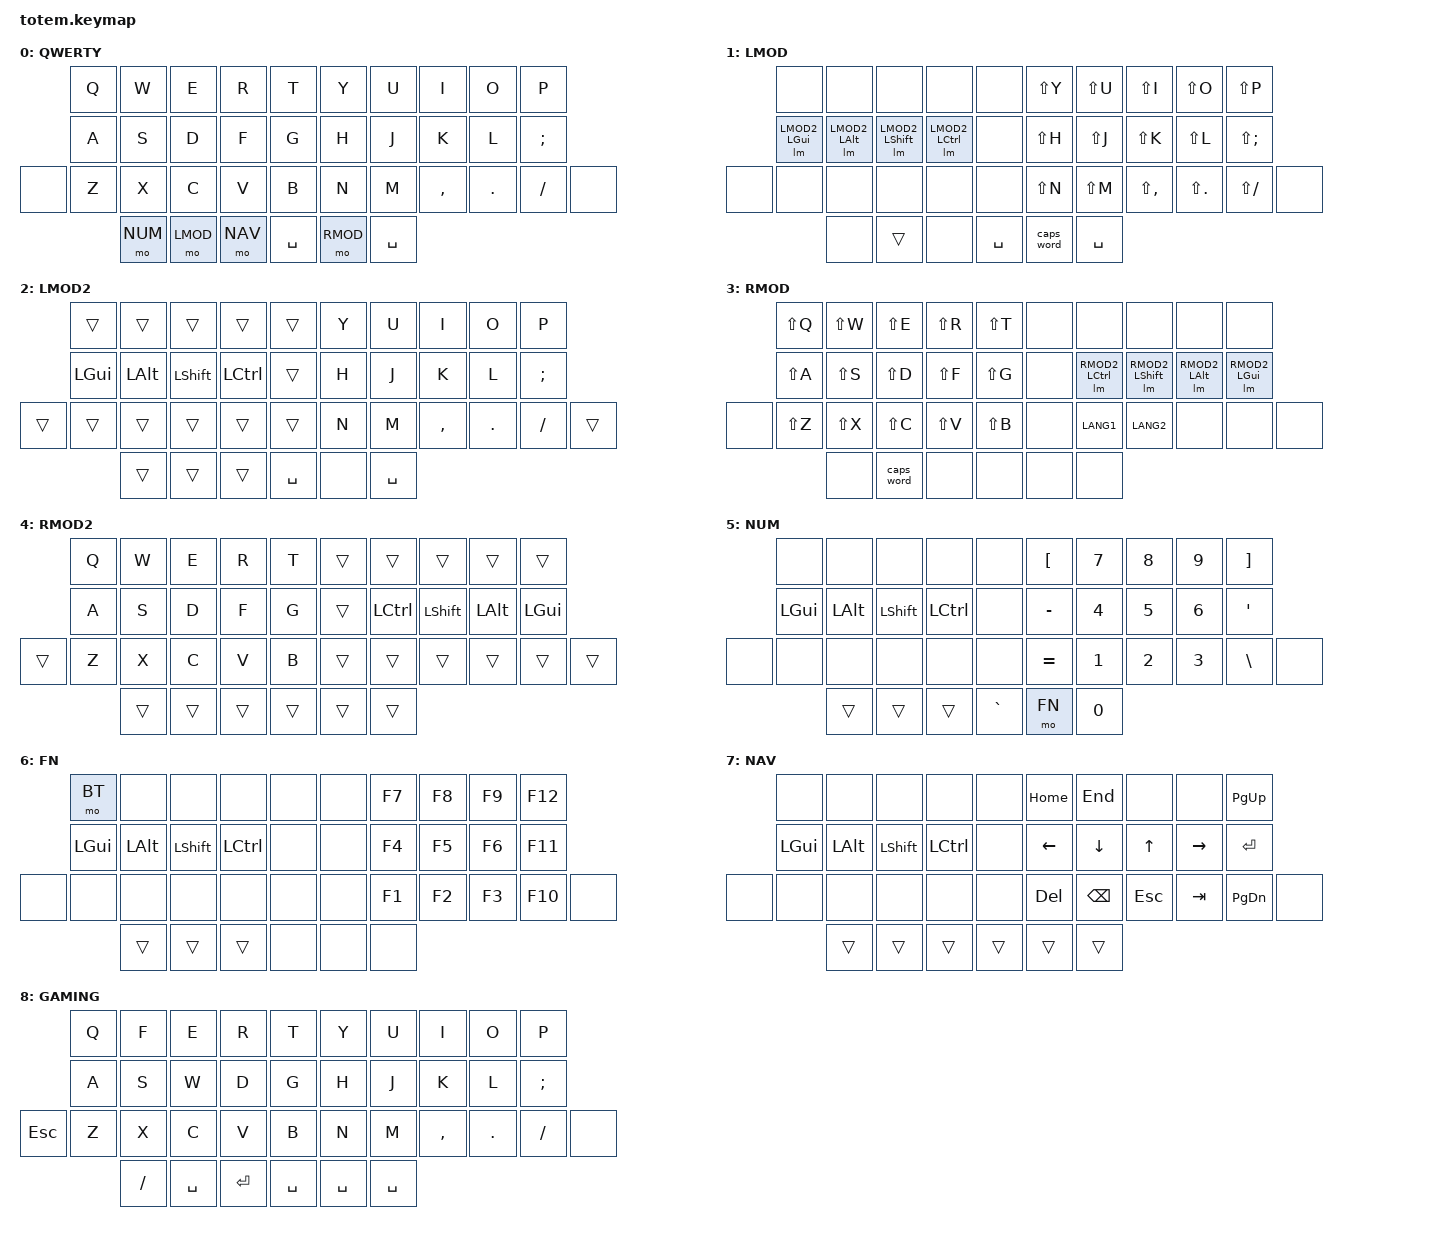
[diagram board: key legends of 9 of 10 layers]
// QMK default keymap port for Totem
// Mirrors qmk_firmware/keyboards/totem/keymaps/default

#include <behaviors.dtsi>
#include <dt-bindings/zmk/bt.h>
#include <dt-bindings/zmk/keys.h>

#define QWERTY 0
#define LMOD   1
#define LMOD2  2
#define RMOD   3
#define RMOD2  4
#define NUM    5
#define FN     6
#define NAV    7
#define GAMING 8
#define BT    9


/ {
    behaviors {
        lm: lm {
            compatible = "zmk,behavior-macro-two-param";
            wait-ms = <0>;
            tap-ms = <0>;
            #binding-cells = <2>;
            bindings
                = <&macro_param_1to1>
                , <&macro_press &mo MACRO_PLACEHOLDER>
                , <&macro_param_2to1>
                , <&macro_press &kp MACRO_PLACEHOLDER>
                , <&macro_pause_for_release>
                , <&macro_param_2to1>
                , <&macro_release &kp MACRO_PLACEHOLDER>
                , <&macro_param_1to1>
                , <&macro_release &mo MACRO_PLACEHOLDER>
                ;
        };
    };

    keymap {
        compatible = "zmk,keymap";

        qwerty_layer {
            label = "QWERTY";
            bindings = <
             &kp Q       &kp W       &kp E        &kp R        &kp T        &kp Y     &kp U            &kp I        &kp O       &kp P
             &kp A       &kp S       &kp D        &kp F        &kp G        &kp H     &kp J            &kp K        &kp L       &kp SEMICOLON
    &none      &kp Z       &kp X        &kp C        &kp V        &kp B        &kp N     &kp M            &kp COMMA    &kp DOT     &kp FSLH     &none
                             &mo NUM    &mo LMOD     &mo NAV      &kp SPACE    &mo RMOD  &kp SPACE
            >;
        };

        lmod_layer {
            label = "LMOD";
            bindings = <
             &none        &none        &none         &none         &none        &kp LS(Y)   &kp LS(U)        &kp LS(I)        &kp LS(O)         &kp LS(P)
             &lm LMOD2 LGUI &lm LMOD2 LALT &lm LMOD2 LSHFT &lm LMOD2 LCTRL &none        &kp LS(H)   &kp LS(J)        &kp LS(K)        &kp LS(L)         &kp LS(SEMICOLON)
    &none       &none        &none         &none         &none        &none        &kp LS(N)   &kp LS(M)        &kp LS(COMMA)    &kp LS(DOT)       &kp LS(FSLH)    &none
                              &none        &trans        &none        &kp SPACE    &caps_word  &kp SPACE
            >;
        };

        lmod2_layer {
            label = "LMOD2";
            bindings = <
             &trans   &trans   &trans   &trans   &trans   &kp Y     &kp U    &kp I    &kp O   &kp P
             &kp LGUI &kp LALT &kp LSHFT &kp LCTRL &trans   &kp H     &kp J    &kp K    &kp L   &kp SEMICOLON
    &trans  &trans   &trans   &trans   &trans   &trans   &kp N     &kp M    &kp COMMA &kp DOT &kp FSLH &trans
                         &trans  &trans  &trans  &kp SPACE  &none     &kp SPACE
            >;
        };

        rmod_layer {
            label = "RMOD";
            bindings = <
             &kp LS(Q)   &kp LS(W)   &kp LS(E)   &kp LS(R)   &kp LS(T)   &none        &none         &none          &none          &none
             &kp LS(A)   &kp LS(S)   &kp LS(D)   &kp LS(F)   &kp LS(G)   &none        &lm RMOD2 LCTRL &lm RMOD2 LSHFT &lm RMOD2 LALT &lm RMOD2 LGUI
    &none    &kp LS(Z)   &kp LS(X)   &kp LS(C)   &kp LS(V)   &kp LS(B)   &none        &kp LANG1     &kp LANG2      &none          &none        &none
                          &none       &caps_word  &none       &none        &none         &none
            >;
        };

        rmod2_layer {
            label = "RMOD2";
            bindings = <
             &kp Q   &kp W   &kp E   &kp R   &kp T   &trans &trans &trans &trans &trans
             &kp A   &kp S   &kp D   &kp F   &kp G   &trans &kp LCTRL &kp LSHFT &kp LALT &kp LGUI
    &trans  &kp Z   &kp X   &kp C   &kp V   &kp B   &trans &trans &trans &trans &trans &trans
                      &trans &trans &trans &trans &trans &trans
            >;
        };

        num_layer {
            label = "NUM";
            bindings = <
             &none   &none   &none    &none    &none    &kp LBKT  &kp N7   &kp N8   &kp N9   &kp RBKT
             &kp LGUI &kp LALT &kp LSHFT &kp LCTRL &none &kp MINUS &kp N4 &kp N5 &kp N6 &kp SQT
    &none   &none   &none    &none    &none    &none    &kp EQUAL &kp N1 &kp N2 &kp N3 &kp BSLH &none
                      &trans &trans   &trans   &kp GRAVE &mo FN   &kp N0
            >;
        };

        fn_layer {
            label = "FN";
            bindings = <
             &mo BT  &none  &none  &none  &none  &none  &kp F7  &kp F8  &kp F9  &kp F12
             &kp LGUI &kp LALT &kp LSHFT &kp LCTRL &none &none &kp F4  &kp F5  &kp F6  &kp F11
    &none  &none  &none  &none  &none  &none  &none  &kp F1  &kp F2  &kp F3  &kp F10 &none
                   &trans &trans &trans &none  &none &none
            >;
        };

        nav_layer {
            label = "NAV";
            bindings = <
             &none  &none  &none   &none   &none   &kp HOME   &kp END     &none       &none      &kp PG_UP
             &kp LGUI &kp LALT &kp LSHFT &kp LCTRL &none  &kp LEFT  &kp DOWN   &kp UP     &kp RIGHT &kp ENTER
    &none  &none  &none   &none   &none   &none   &kp DEL   &kp BSPC  &kp ESC   &kp TAB   &kp PG_DN &none
                   &trans &trans  &trans  &trans   &trans   &trans
            >;
        };

        gaming_layer {
            label = "GAMING";
            bindings = <
             &kp Q     &kp F     &kp E     &kp R     &kp T     &kp Y     &kp U      &kp I      &kp O      &kp P
             &kp A     &kp S     &kp W     &kp D     &kp G     &kp H     &kp J      &kp K      &kp L      &kp SEMICOLON
    &kp ESC  &kp Z     &kp X     &kp C     &kp V     &kp B     &kp N     &kp M      &kp COMMA  &kp DOT    &kp FSLH    &none
                    &kp FSLH   &kp SPACE &kp ENTER &kp SPACE &kp SPACE &kp SPACE
            >;
        };

        bt_layer {
            label = "BT";
            bindings = <
             &none   &none   &none    &none    &none    &none  &none   &none  &none  &bt BT_CLR
             &kp LGUI &kp LALT &kp LSHFT &kp LCTRL &none &none  &bt BT_SEL 3 &bt BT_SEL 4 &none  &none
    &none   &none   &none    &none    &none    &none   &none  &bt BT_SEL 0 &bt BT_SEL 1 &bt BT_SEL 2 &none
                      &trans &trans   &trans   &none &none  &none
            >;
        };

    };
};
